# jbr_MDR1986VE3 register map
Registers are 32-bit, access not given, no defined reset value unless marked. A register's access mark holds for its fields unless they carry their own. Addresses are absolute; registers are grouped by the start of their names; [hi:lo] are bit positions; {n}, {i} and the like mark numbered series.

## GPIOB
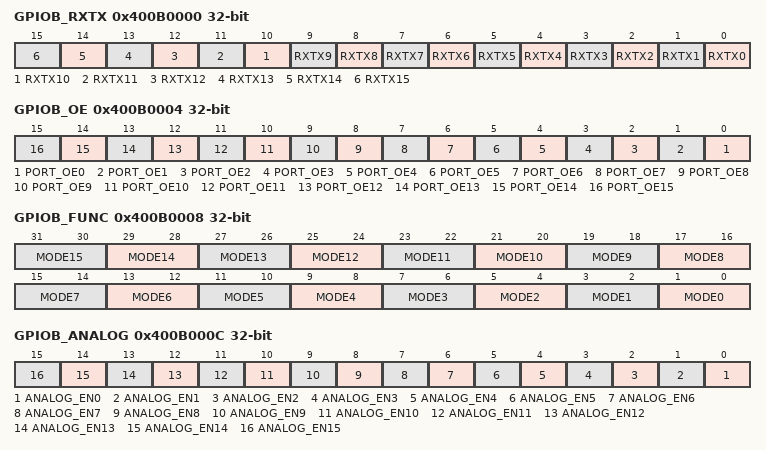
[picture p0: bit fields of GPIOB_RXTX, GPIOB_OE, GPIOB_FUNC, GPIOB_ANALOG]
0x400B0000 GPIOB_RXTX
  [n] RXTX{n} (n=0..15)
0x400B0004 GPIOB_OE
  [n] PORT_OE{n} (n=0..15)
0x400B0008 GPIOB_FUNC
  [2n+1:2n] MODE{n} (n=0..15)
0x400B000C GPIOB_ANALOG
  [n] ANALOG_EN{n} (n=0..15)
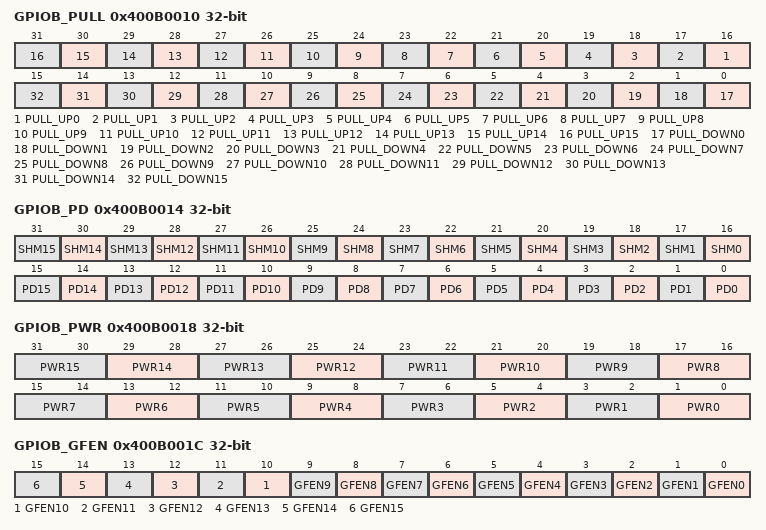
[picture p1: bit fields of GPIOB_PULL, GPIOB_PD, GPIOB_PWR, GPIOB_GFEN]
0x400B0010 GPIOB_PULL
  [n+16] PULL_UP{n} (n=0..15), [n] PULL_DOWN{n} (n=0..15)
0x400B0014 GPIOB_PD
  [n+16] SHM{n} (n=0..15), [n] PD{n} (n=0..15)
0x400B0018 GPIOB_PWR
  [2n+1:2n] PWR{n} (n=0..15)
0x400B001C GPIOB_GFEN
  [n] GFEN{n} (n=0..15)
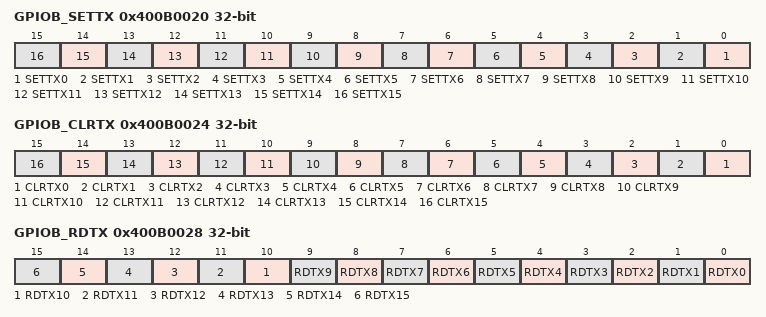
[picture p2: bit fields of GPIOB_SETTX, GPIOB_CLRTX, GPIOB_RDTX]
0x400B0020 GPIOB_SETTX
  [n] SETTX{n} (n=0..15)
0x400B0024 GPIOB_CLRTX
  [n] CLRTX{n} (n=0..15)
0x400B0028 GPIOB_RDTX
  [n] RDTX{n} (n=0..15)

## GPIOC
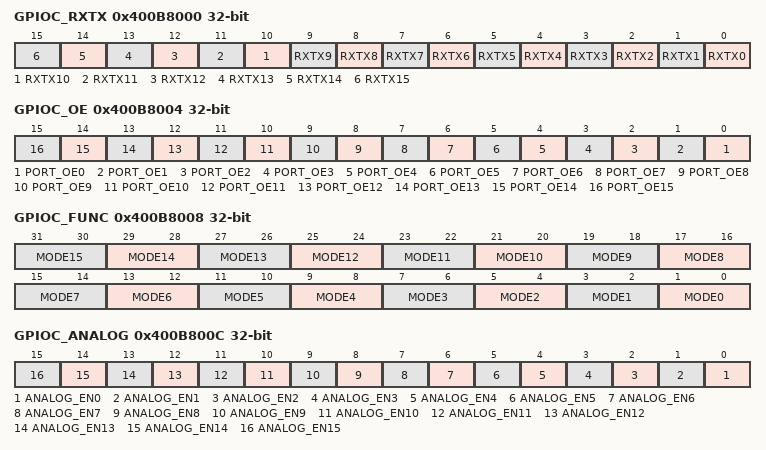
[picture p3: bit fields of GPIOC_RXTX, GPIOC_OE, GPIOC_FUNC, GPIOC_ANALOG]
0x400B8000 GPIOC_RXTX
  [n] RXTX{n} (n=0..15)
0x400B8004 GPIOC_OE
  [n] PORT_OE{n} (n=0..15)
0x400B8008 GPIOC_FUNC
  [2n+1:2n] MODE{n} (n=0..15)
0x400B800C GPIOC_ANALOG
  [n] ANALOG_EN{n} (n=0..15)
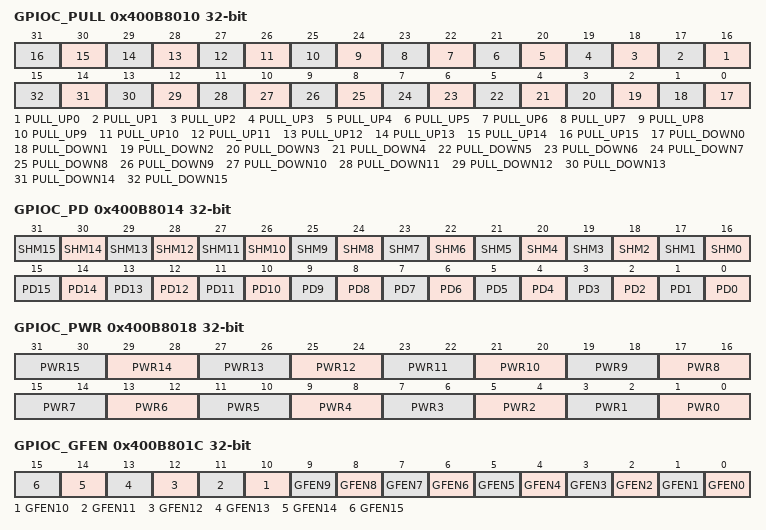
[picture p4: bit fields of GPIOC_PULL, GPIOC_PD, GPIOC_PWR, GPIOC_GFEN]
0x400B8010 GPIOC_PULL
  [n+16] PULL_UP{n} (n=0..15), [n] PULL_DOWN{n} (n=0..15)
0x400B8014 GPIOC_PD
  [n+16] SHM{n} (n=0..15), [n] PD{n} (n=0..15)
0x400B8018 GPIOC_PWR
  [2n+1:2n] PWR{n} (n=0..15)
0x400B801C GPIOC_GFEN
  [n] GFEN{n} (n=0..15)
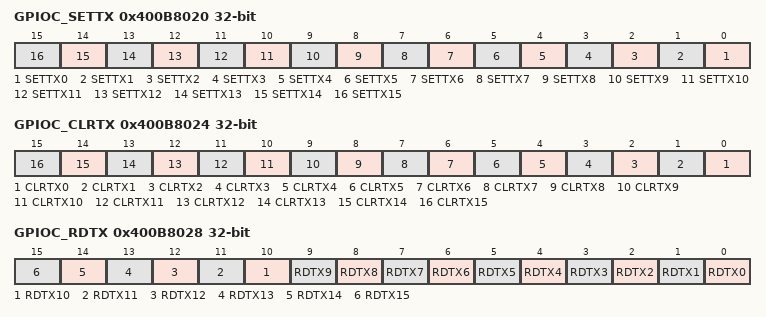
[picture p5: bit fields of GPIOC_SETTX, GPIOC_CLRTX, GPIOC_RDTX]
0x400B8020 GPIOC_SETTX
  [n] SETTX{n} (n=0..15)
0x400B8024 GPIOC_CLRTX
  [n] CLRTX{n} (n=0..15)
0x400B8028 GPIOC_RDTX
  [n] RDTX{n} (n=0..15)

## GPIOD
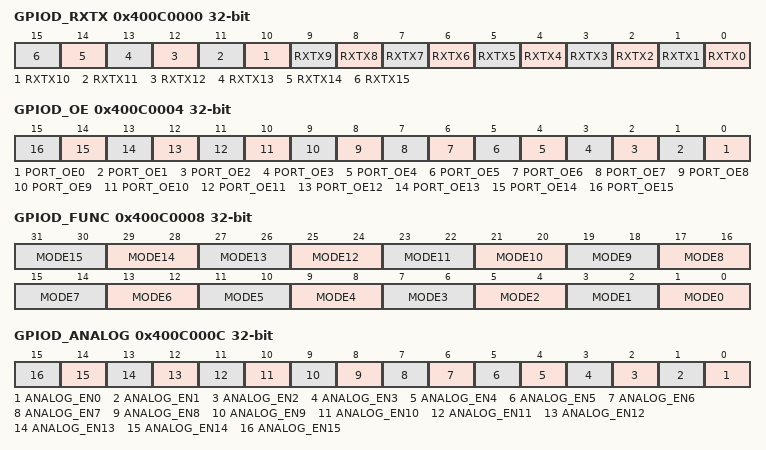
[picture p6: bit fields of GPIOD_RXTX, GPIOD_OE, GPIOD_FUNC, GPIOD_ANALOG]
0x400C0000 GPIOD_RXTX
  [n] RXTX{n} (n=0..15)
0x400C0004 GPIOD_OE
  [n] PORT_OE{n} (n=0..15)
0x400C0008 GPIOD_FUNC
  [2n+1:2n] MODE{n} (n=0..15)
0x400C000C GPIOD_ANALOG
  [n] ANALOG_EN{n} (n=0..15)
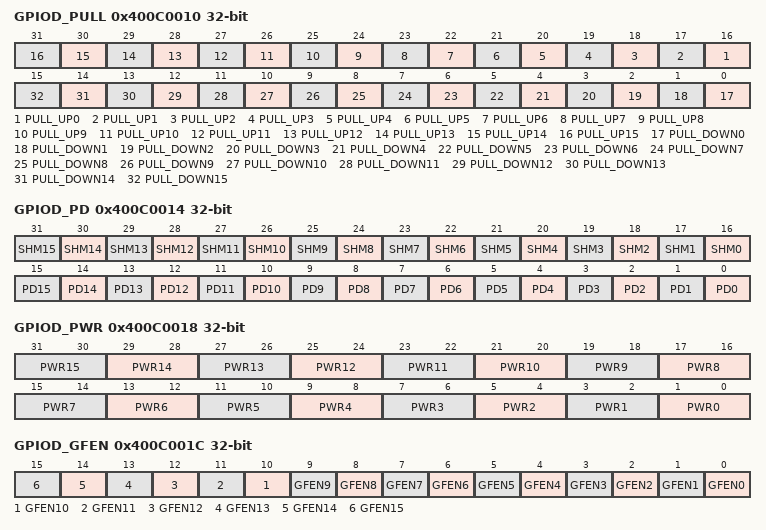
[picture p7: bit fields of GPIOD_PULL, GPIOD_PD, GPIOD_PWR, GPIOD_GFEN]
0x400C0010 GPIOD_PULL
  [n+16] PULL_UP{n} (n=0..15), [n] PULL_DOWN{n} (n=0..15)
0x400C0014 GPIOD_PD
  [n+16] SHM{n} (n=0..15), [n] PD{n} (n=0..15)
0x400C0018 GPIOD_PWR
  [2n+1:2n] PWR{n} (n=0..15)
0x400C001C GPIOD_GFEN
  [n] GFEN{n} (n=0..15)
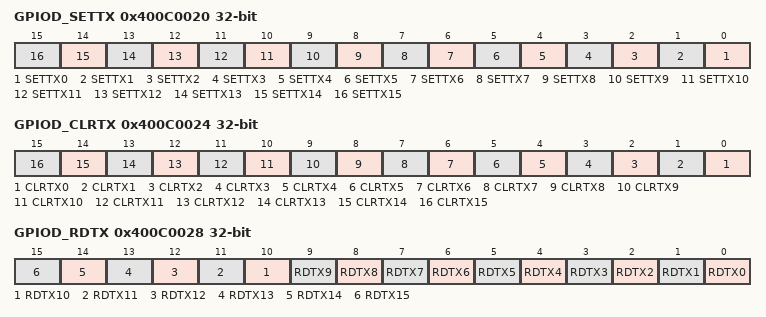
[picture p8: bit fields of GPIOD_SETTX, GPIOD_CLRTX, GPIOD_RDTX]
0x400C0020 GPIOD_SETTX
  [n] SETTX{n} (n=0..15)
0x400C0024 GPIOD_CLRTX
  [n] CLRTX{n} (n=0..15)
0x400C0028 GPIOD_RDTX
  [n] RDTX{n} (n=0..15)

## GPIOE
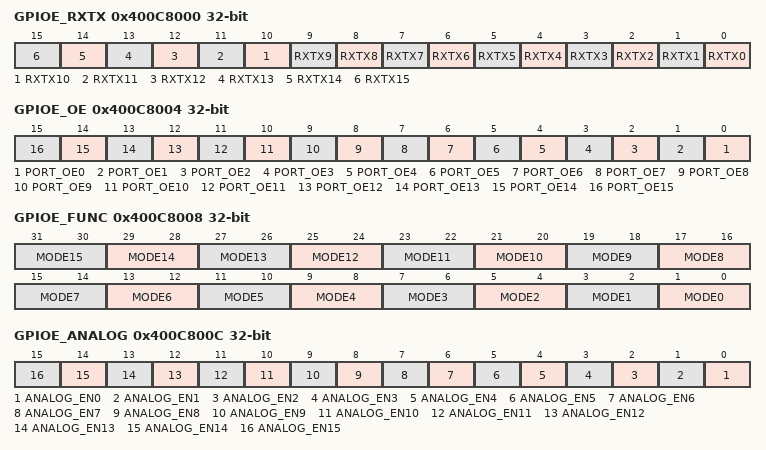
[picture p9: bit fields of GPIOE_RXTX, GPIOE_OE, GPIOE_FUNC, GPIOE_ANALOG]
0x400C8000 GPIOE_RXTX
  [n] RXTX{n} (n=0..15)
0x400C8004 GPIOE_OE
  [n] PORT_OE{n} (n=0..15)
0x400C8008 GPIOE_FUNC
  [2n+1:2n] MODE{n} (n=0..15)
0x400C800C GPIOE_ANALOG
  [n] ANALOG_EN{n} (n=0..15)
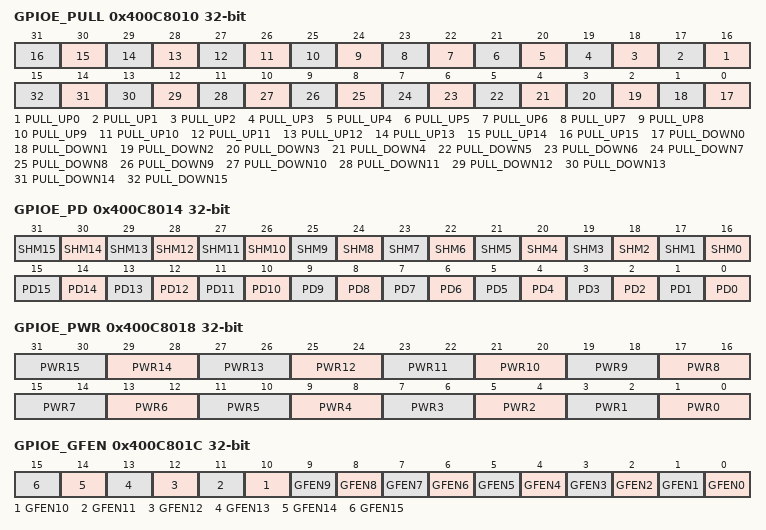
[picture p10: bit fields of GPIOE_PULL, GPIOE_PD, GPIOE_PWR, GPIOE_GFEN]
0x400C8010 GPIOE_PULL
  [n+16] PULL_UP{n} (n=0..15), [n] PULL_DOWN{n} (n=0..15)
0x400C8014 GPIOE_PD
  [n+16] SHM{n} (n=0..15), [n] PD{n} (n=0..15)
0x400C8018 GPIOE_PWR
  [2n+1:2n] PWR{n} (n=0..15)
0x400C801C GPIOE_GFEN
  [n] GFEN{n} (n=0..15)
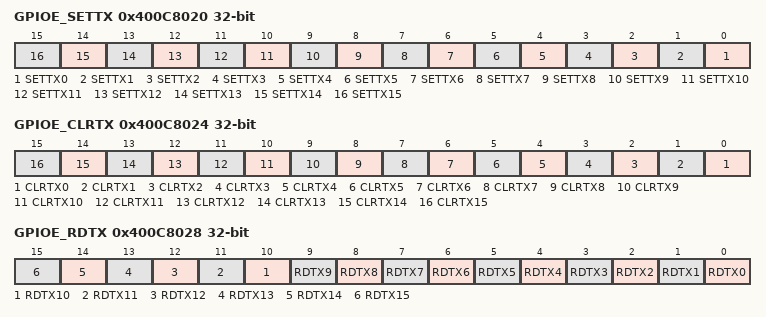
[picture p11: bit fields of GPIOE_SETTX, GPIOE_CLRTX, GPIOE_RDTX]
0x400C8020 GPIOE_SETTX
  [n] SETTX{n} (n=0..15)
0x400C8024 GPIOE_CLRTX
  [n] CLRTX{n} (n=0..15)
0x400C8028 GPIOE_RDTX
  [n] RDTX{n} (n=0..15)

## GPIOF
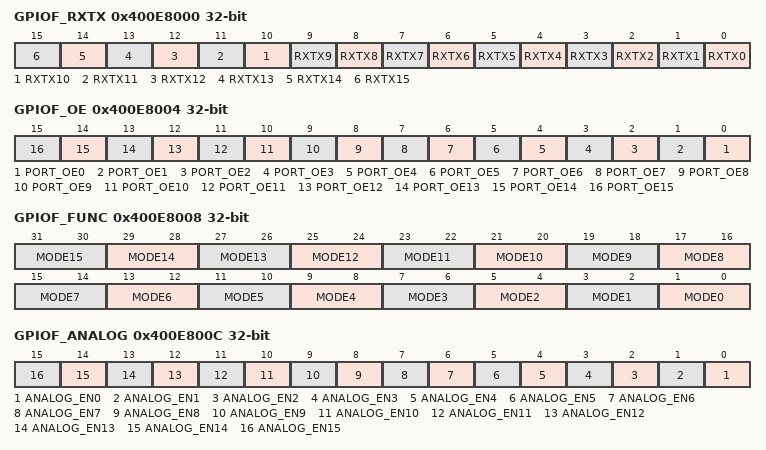
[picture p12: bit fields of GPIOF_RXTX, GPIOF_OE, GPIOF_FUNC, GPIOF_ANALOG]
0x400E8000 GPIOF_RXTX
  [n] RXTX{n} (n=0..15)
0x400E8004 GPIOF_OE
  [n] PORT_OE{n} (n=0..15)
0x400E8008 GPIOF_FUNC
  [2n+1:2n] MODE{n} (n=0..15)
0x400E800C GPIOF_ANALOG
  [n] ANALOG_EN{n} (n=0..15)
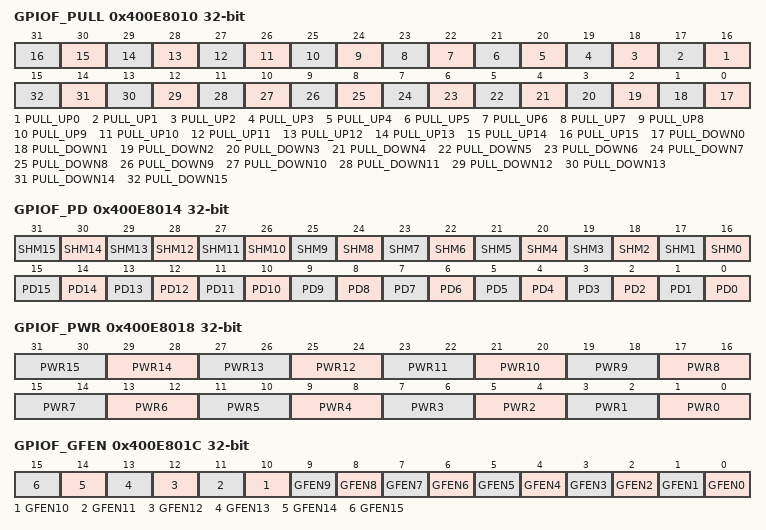
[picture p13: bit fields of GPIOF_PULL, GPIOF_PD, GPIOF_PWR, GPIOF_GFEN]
0x400E8010 GPIOF_PULL
  [n+16] PULL_UP{n} (n=0..15), [n] PULL_DOWN{n} (n=0..15)
0x400E8014 GPIOF_PD
  [n+16] SHM{n} (n=0..15), [n] PD{n} (n=0..15)
0x400E8018 GPIOF_PWR
  [2n+1:2n] PWR{n} (n=0..15)
0x400E801C GPIOF_GFEN
  [n] GFEN{n} (n=0..15)
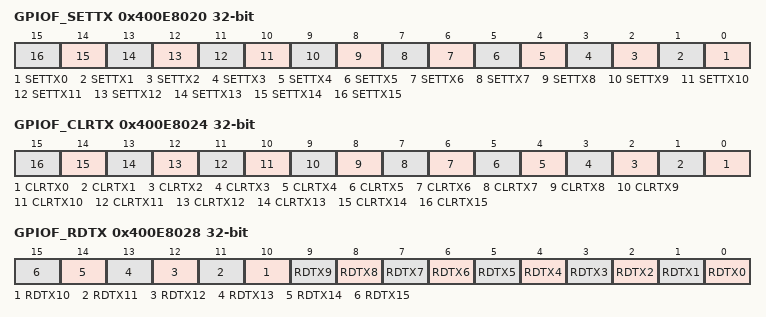
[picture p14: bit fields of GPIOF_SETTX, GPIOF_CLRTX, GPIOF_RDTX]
0x400E8020 GPIOF_SETTX
  [n] SETTX{n} (n=0..15)
0x400E8024 GPIOF_CLRTX
  [n] CLRTX{n} (n=0..15)
0x400E8028 GPIOF_RDTX
  [n] RDTX{n} (n=0..15)

## GPIOG
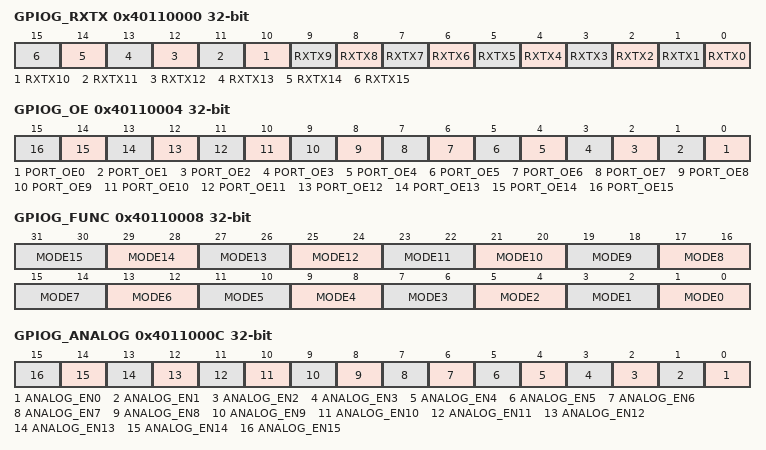
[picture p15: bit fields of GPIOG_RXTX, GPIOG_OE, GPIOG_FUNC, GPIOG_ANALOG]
0x40110000 GPIOG_RXTX
  [n] RXTX{n} (n=0..15)
0x40110004 GPIOG_OE
  [n] PORT_OE{n} (n=0..15)
0x40110008 GPIOG_FUNC
  [2n+1:2n] MODE{n} (n=0..15)
0x4011000C GPIOG_ANALOG
  [n] ANALOG_EN{n} (n=0..15)
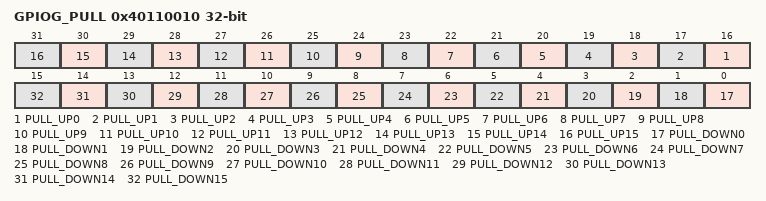
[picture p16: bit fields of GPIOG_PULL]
0x40110010 GPIOG_PULL
  [n+16] PULL_UP{n} (n=0..15), [n] PULL_DOWN{n} (n=0..15)
0x40110014 GPIOG_PD
  [n+16] SHM{n} (n=0..15), [n] PD{n} (n=0..15)
0x40110018 GPIOG_PWR
  [2n+1:2n] PWR{n} (n=0..15)
0x4011001C GPIOG_GFEN
  [n] GFEN{n} (n=0..15)
0x40110020 GPIOG_SETTX
  [n] SETTX{n} (n=0..15)
0x40110024 GPIOG_CLRTX
  [n] CLRTX{n} (n=0..15)
0x40110028 GPIOG_RDTX
  [n] RDTX{n} (n=0..15)
